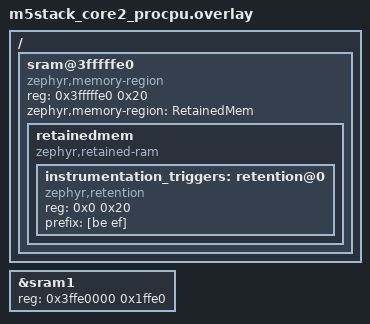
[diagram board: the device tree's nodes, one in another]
/*
 * Copyright 2023 Linaro
 *
 * SPDX-License-Identifier: Apache-2.0
 */

/ {
	sram@3fffffe0 {
		compatible = "zephyr,memory-region", "mmio-sram";
		reg = <0x3fffffe0 0x20>;
		zephyr,memory-region = "RetainedMem";
		status = "okay";

		retainedmem {
			compatible = "zephyr,retained-ram";
			status = "okay";
			#address-cells = <1>;
			#size-cells = <1>;

			instrumentation_triggers: retention@0 {
				compatible = "zephyr,retention";
				status = "okay";

				reg = <0x0 0x20>;

				prefix = [be ef];
			};
		};
	};
};

&sram1 {
	reg = <0x3ffe0000 0x1ffe0>;
};
